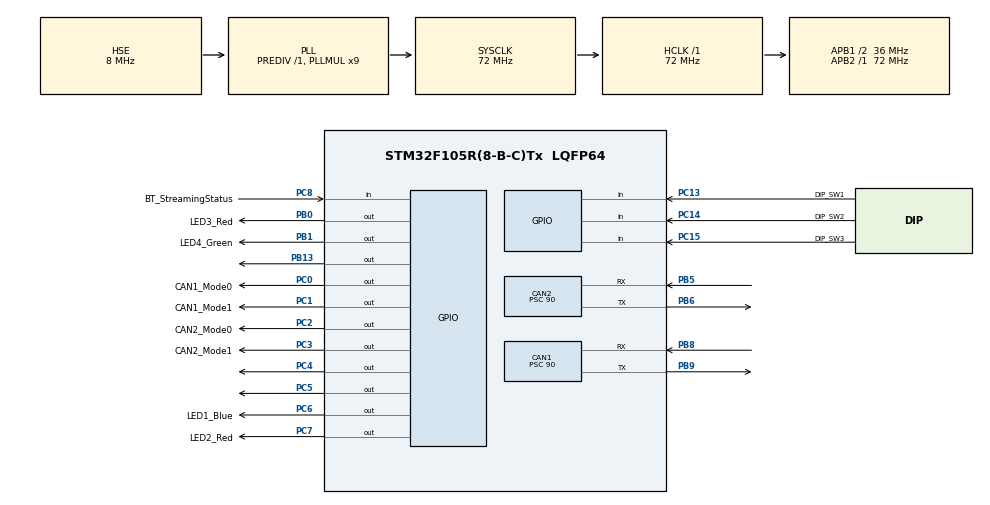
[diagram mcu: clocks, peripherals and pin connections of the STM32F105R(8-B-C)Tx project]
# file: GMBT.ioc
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CAN1.ABOM=ENABLE
CAN1.AWUM=ENABLE
CAN1.BS1=CAN_BS1_8TQ
CAN1.BS2=CAN_BS2_3TQ
CAN1.CalculateTimeBit=30000
CAN1.CalculateTimeQuantum=2500.0
CAN1.NART=DISABLE
CAN1.Prescaler=90
CAN1.TTCM=DISABLE
CAN1.TXFP=ENABLE
CAN2.ABOM=ENABLE
CAN2.AWUM=ENABLE
CAN2.BS1=CAN_BS1_8TQ
CAN2.BS2=CAN_BS2_3TQ
CAN2.CalculateTimeBit=30000
CAN2.CalculateTimeQuantum=2500.0
CAN2.NART=DISABLE
CAN2.Prescaler=90
CAN2.TXFP=ENABLE
Mcu.Family=STM32F1
Mcu.Name=STM32F105R(8-B-C)Tx
Mcu.Package=LQFP64
NVIC.CAN1_RX0_IRQn=true\:0\:0\:false\:false\:true\:true
NVIC.CAN2_RX0_IRQn=true\:0\:0\:false\:false\:true\:true
NVIC.PriorityGroup=NVIC_PRIORITYGROUP_4
PA0-WKUP.Mode=SYS_WakeUp0
PA0-WKUP.Signal=SYS_WKUP
PA11.Signal=USB_OTG_FS_DM
PA12.Signal=USB_OTG_FS_DP
PA13.Mode=JTAG_5_pins
PA13.Signal=SYS_JTMS-SWDIO
PA14.Mode=JTAG_5_pins
PA14.Signal=SYS_JTCK-SWCLK
PA15.Mode=JTAG_5_pins
PA15.Signal=SYS_JTDI
PB0.GPIO_Label=LED3_Red
PB0.Signal=GPIO_Output
PB1.GPIO_Label=LED4_Green
PB1.Signal=GPIO_Output
PB13.Signal=GPIO_Output
PB3.Mode=JTAG_5_pins
PB3.Signal=SYS_JTDO
PB4.Mode=JTAG_5_pins
PB4.Signal=SYS_NJTRST
PB5.GPIO_PuPd=GPIO_PULLUP
PB5.Mode=Slave
PB5.Signal=CAN2_RX
PB6.GPIO_Speed=GPIO_SPEED_FREQ_HIGH
PB6.Mode=Slave
PB6.Signal=CAN2_TX
PB8.GPIO_PuPd=GPIO_PULLUP
PB8.Mode=Master
PB8.Signal=CAN1_RX
PB9.GPIO_Speed=GPIO_SPEED_FREQ_HIGH
PB9.Mode=Master
PB9.Signal=CAN1_TX
PC0.GPIO_Label=CAN1_Mode0
PC0.Signal=GPIO_Output
PC1.GPIO_Label=CAN1_Mode1
PC1.Signal=GPIO_Output
PC13-TAMPER-RTC.GPIO_Label=DIP_SW1
PC13-TAMPER-RTC.GPIO_PuPd=GPIO_PULLUP
PC13-TAMPER-RTC.Signal=GPIO_Input
PC14-OSC32_IN.GPIO_Label=DIP_SW2
PC14-OSC32_IN.GPIO_PuPd=GPIO_PULLUP
PC14-OSC32_IN.Signal=GPIO_Input
PC15-OSC32_OUT.GPIO_Label=DIP_SW3
PC15-OSC32_OUT.GPIO_PuPd=GPIO_PULLUP
PC15-OSC32_OUT.Signal=GPIO_Input
PC2.GPIO_Label=CAN2_Mode0
PC2.Signal=GPIO_Output
PC3.GPIO_Label=CAN2_Mode1
PC3.Signal=GPIO_Output
PC4.Signal=GPIO_Output
PC5.Signal=GPIO_Output
PC6.GPIO_Label=LED1_Blue
PC6.Signal=GPIO_Output
PC7.GPIO_Label=LED2_Red
PC7.Signal=GPIO_Output
PC8.GPIO_Label=BT_StreamingStatus
PC8.Signal=GPIO_Input
PD0-OSC_IN.Mode=HSE-External-Oscillator
PD0-OSC_IN.Signal=RCC_OSC_IN
PD1-OSC_OUT.Mode=HSE-External-Oscillator
PD1-OSC_OUT.Signal=RCC_OSC_OUT
ProjectManager.HeapSize=0x200
ProjectManager.StackSize=0x400
ProjectManager.TargetToolchain=MDK-ARM V5
RCC.AHBFreq_Value=72000000
RCC.APB1CLKDivider=RCC_HCLK_DIV2
RCC.APB1Freq_Value=36000000
RCC.APB1TimFreq_Value=72000000
RCC.APB2Freq_Value=72000000
RCC.APB2TimFreq_Value=72000000
RCC.HCLKFreq_Value=72000000
RCC.PLLMUL=RCC_PLL_MUL9
RCC.PLLSourceVirtual=RCC_PLLSOURCE_HSE
RCC.SYSCLKFreq_VALUE=72000000
RCC.SYSCLKSource=RCC_SYSCLKSOURCE_PLLCLK
RCC.USBFreq_Value=48000000
board=GMBT

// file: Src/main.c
/**
  ******************************************************************************
  * @file           : main.c
  * @brief          : Main program body
  ******************************************************************************
  ** This notice applies to any and all portions of this file
  * that are not between comment pairs USER CODE BEGIN and
  * USER CODE END. Other portions of this file, whether
  * inserted by the user or by software development tools
  * are owned by their respective copyright owners.
  *
  * COPYRIGHT(c) 2018 STMicroelectronics
  *
  * Redistribution and use in source and binary forms, with or without modification,
  * are permitted provided that the following conditions are met:
  *   1. Redistributions of source code must retain the above copyright notice,
  *      this list of conditions and the following disclaimer.
  *   2. Redistributions in binary form must reproduce the above copyright notice,
  *      this list of conditions and the following disclaimer in the documentation
  *      and/or other materials provided with the distribution.
  *   3. Neither the name of STMicroelectronics nor the names of its contributors
  *      may be used to endorse or promote products derived from this software
  *      without specific prior written permission.
  *
  * THIS SOFTWARE IS PROVIDED BY THE COPYRIGHT HOLDERS AND CONTRIBUTORS "AS IS"
  * AND ANY EXPRESS OR IMPLIED WARRANTIES, INCLUDING, BUT NOT LIMITED TO, THE
  * IMPLIED WARRANTIES OF MERCHANTABILITY AND FITNESS FOR A PARTICULAR PURPOSE ARE
  * DISCLAIMED. IN NO EVENT SHALL THE COPYRIGHT HOLDER OR CONTRIBUTORS BE LIABLE
  * FOR ANY DIRECT, INDIRECT, INCIDENTAL, SPECIAL, EXEMPLARY, OR CONSEQUENTIAL
  * DAMAGES (INCLUDING, BUT NOT LIMITED TO, PROCUREMENT OF SUBSTITUTE GOODS OR
  * SERVICES; LOSS OF USE, DATA, OR PROFITS; OR BUSINESS INTERRUPTION) HOWEVER
  * CAUSED AND ON ANY THEORY OF LIABILITY, WHETHER IN CONTRACT, STRICT LIABILITY,
  * OR TORT (INCLUDING NEGLIGENCE OR OTHERWISE) ARISING IN ANY WAY OUT OF THE USE
  * OF THIS SOFTWARE, EVEN IF ADVISED OF THE POSSIBILITY OF SUCH DAMAGE.
  *
  ******************************************************************************
  */
#include "main.h"
#include "stm32f1xx_hal.h"
#include "can.h"
#include "gpio.h"

/* USER CODE BEGIN Includes */
#include "CAN_TransceiverGMLAN.h"
#include "CAN_Buffer.h"
#include "PollingRoutines.h"
#include "TimerCallback.h"
/* USER CODE END Includes */

/* USER CODE BEGIN PV */
/* Private variables ---------------------------------------------------------*/

/* USER CODE END PV */

void SystemClock_Config(void);

/* USER CODE BEGIN PFP */
/* Private function prototypes -----------------------------------------------*/

/* USER CODE END PFP */

int main(void)
{

  /* MCU Configuration----------------------------------------------------------*/

  /* Reset of all peripherals, Initializes the Flash interface and the Systick. */
  HAL_Init();

  /* Configure the system clock */
  SystemClock_Config();

  /* Initialize all configured peripherals */
  MX_GPIO_Init();
  MX_CAN1_Init();
  MX_CAN2_Init();
  /* USER CODE BEGIN 2 */
	InitDualCanTransceiver();
	SetCanFilter();
	InitTxMessagesCAN1();
	InitTxMessagesCAN2();

	CreateTimerCallback(GotoSleepCallbackFunc,2000, NO_REPEAT_TIMER);
  /* USER CODE END 2 */

  /* Infinite loop */
  /* USER CODE BEGIN WHILE */
  while (1)
  {
		CheckPollingRoutines();
  /* USER CODE END WHILE */

  }

}

void SystemClock_Config(void)
{

  RCC_OscInitTypeDef RCC_OscInitStruct;
  RCC_ClkInitTypeDef RCC_ClkInitStruct;

    /**Initializes the CPU, AHB and APB busses clocks
    */
  RCC_OscInitStruct.OscillatorType = RCC_OSCILLATORTYPE_HSE;
  RCC_OscInitStruct.HSEState = RCC_HSE_ON;
  RCC_OscInitStruct.HSEPredivValue = RCC_HSE_PREDIV_DIV1;
  RCC_OscInitStruct.HSIState = RCC_HSI_ON;
  RCC_OscInitStruct.Prediv1Source = RCC_PREDIV1_SOURCE_HSE;
  RCC_OscInitStruct.PLL.PLLState = RCC_PLL_ON;
  RCC_OscInitStruct.PLL.PLLSource = RCC_PLLSOURCE_HSE;
  RCC_OscInitStruct.PLL.PLLMUL = RCC_PLL_MUL9;
  RCC_OscInitStruct.PLL2.PLL2State = RCC_PLL_NONE;
  if (HAL_RCC_OscConfig(&RCC_OscInitStruct) != HAL_OK)
  {
    _Error_Handler(__FILE__, __LINE__);
  }

    /**Initializes the CPU, AHB and APB busses clocks
    */
  RCC_ClkInitStruct.ClockType = RCC_CLOCKTYPE_HCLK|RCC_CLOCKTYPE_SYSCLK
                              |RCC_CLOCKTYPE_PCLK1|RCC_CLOCKTYPE_PCLK2;
  RCC_ClkInitStruct.SYSCLKSource = RCC_SYSCLKSOURCE_PLLCLK;
  RCC_ClkInitStruct.AHBCLKDivider = RCC_SYSCLK_DIV1;
  RCC_ClkInitStruct.APB1CLKDivider = RCC_HCLK_DIV2;
  RCC_ClkInitStruct.APB2CLKDivider = RCC_HCLK_DIV1;

  if (HAL_RCC_ClockConfig(&RCC_ClkInitStruct, FLASH_LATENCY_2) != HAL_OK)
  {
    _Error_Handler(__FILE__, __LINE__);
  }

    /**Configure the Systick interrupt time
    */
  HAL_SYSTICK_Config(HAL_RCC_GetHCLKFreq()/1000);

    /**Configure the Systick
    */
  HAL_SYSTICK_CLKSourceConfig(SYSTICK_CLKSOURCE_HCLK);

    /**Configure the Systick interrupt time
    */
  __HAL_RCC_PLLI2S_ENABLE();

  /* SysTick_IRQn interrupt configuration */
  HAL_NVIC_SetPriority(SysTick_IRQn, 0, 0);
}

void _Error_Handler(char *file, int line)
{
  while(1)
  {
  }
}

/************************ (C) COPYRIGHT STMicroelectronics *****END OF FILE****/
